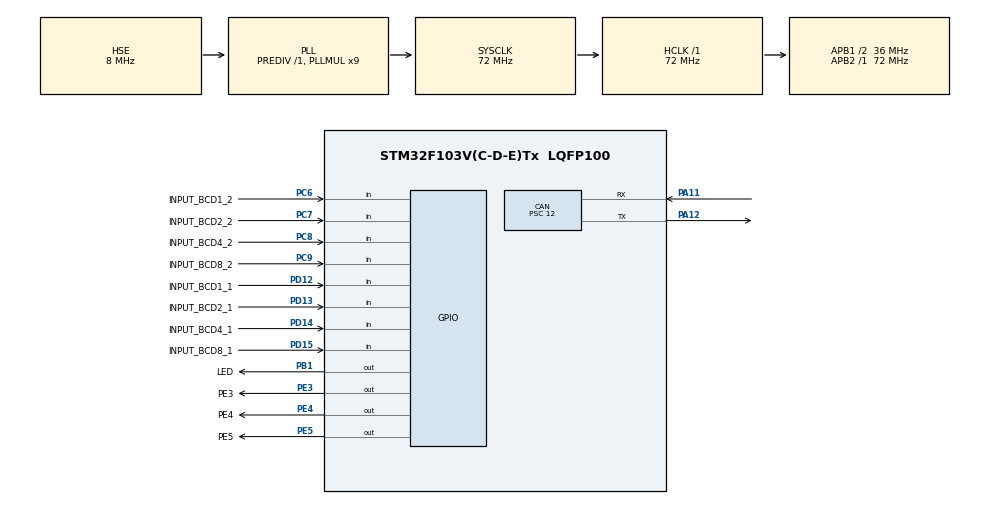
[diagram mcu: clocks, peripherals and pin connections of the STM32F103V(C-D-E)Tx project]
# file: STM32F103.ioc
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CAN.BS1=CAN_BS1_5TQ
CAN.BS2=CAN_BS2_6TQ
CAN.CalculateTimeBit=4000
CAN.CalculateTimeQuantum=333.33333333333337
CAN.Prescaler=12
Mcu.Family=STM32F1
Mcu.Name=STM32F103V(C-D-E)Tx
Mcu.Package=LQFP100
NVIC.PriorityGroup=NVIC_PRIORITYGROUP_4
NVIC.TIM5_IRQn=true\:1\:0\:true\:false\:true\:true
NVIC.USB_LP_CAN1_RX0_IRQn=true\:0\:0\:false\:false\:true\:true
OSC_IN.Mode=HSE-External-Oscillator
OSC_IN.Signal=RCC_OSC_IN
OSC_OUT.Mode=HSE-External-Oscillator
OSC_OUT.Signal=RCC_OSC_OUT
PA11.Mode=Master
PA11.Signal=CAN_RX
PA12.Mode=Master
PA12.Signal=CAN_TX
PA13.Mode=Serial_Wire
PA13.Signal=SYS_JTMS-SWDIO
PA14.Mode=Serial_Wire
PA14.Signal=SYS_JTCK-SWCLK
PB1.GPIO_Label=LED
PB1.Signal=GPIO_Output
PC6.GPIO_Label=INPUT_BCD1_2
PC6.Signal=GPIO_Input
PC7.GPIO_Label=INPUT_BCD2_2
PC7.Signal=GPIO_Input
PC8.GPIO_Label=INPUT_BCD4_2
PC8.Signal=GPIO_Input
PC9.GPIO_Label=INPUT_BCD8_2
PC9.Signal=GPIO_Input
PD12.GPIO_Label=INPUT_BCD1_1
PD12.Signal=GPIO_Input
PD13.GPIO_Label=INPUT_BCD2_1
PD13.Signal=GPIO_Input
PD14.GPIO_Label=INPUT_BCD4_1
PD14.Signal=GPIO_Input
PD15.GPIO_Label=INPUT_BCD8_1
PD15.Signal=GPIO_Input
PE3.GPIO_Label=PE3
PE3.PinState=GPIO_PIN_SET
PE3.Signal=GPIO_Output
PE4.GPIO_Label=PE4
PE4.PinState=GPIO_PIN_SET
PE4.Signal=GPIO_Output
PE5.GPIO_Label=PE5
PE5.PinState=GPIO_PIN_SET
PE5.Signal=GPIO_Output
ProjectManager.HeapSize=0x200
ProjectManager.StackSize=0x400
ProjectManager.TargetToolchain=MDK-ARM V5
RCC.AHBFreq_Value=72000000
RCC.APB1CLKDivider=RCC_HCLK_DIV2
RCC.APB1Freq_Value=36000000
RCC.APB1TimFreq_Value=72000000
RCC.APB2Freq_Value=72000000
RCC.APB2TimFreq_Value=72000000
RCC.HCLKFreq_Value=72000000
RCC.PLLMUL=RCC_PLL_MUL9
RCC.PLLSourceVirtual=RCC_PLLSOURCE_HSE
RCC.SYSCLKFreq_VALUE=72000000
RCC.SYSCLKSource=RCC_SYSCLKSOURCE_PLLCLK
RCC.USBFreq_Value=72000000
TIM5.Period=20000-1
TIM5.Prescaler=7200-1
VP_TIM5_VS_ClockSourceINT.Mode=Internal
board=STM32F103

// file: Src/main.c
/**
  ******************************************************************************
  * File Name          : main.c
  * Description        : Main program body
  ******************************************************************************
  ** This notice applies to any and all portions of this file
  * that are not between comment pairs USER CODE BEGIN and
  * USER CODE END. Other portions of this file, whether
  * inserted by the user or by software development tools
  * are owned by their respective copyright owners.
  *
  * COPYRIGHT(c) 2018 STMicroelectronics
  *
  * Redistribution and use in source and binary forms, with or without modification,
  * are permitted provided that the following conditions are met:
  *   1. Redistributions of source code must retain the above copyright notice,
  *      this list of conditions and the following disclaimer.
  *   2. Redistributions in binary form must reproduce the above copyright notice,
  *      this list of conditions and the following disclaimer in the documentation
  *      and/or other materials provided with the distribution.
  *   3. Neither the name of STMicroelectronics nor the names of its contributors
  *      may be used to endorse or promote products derived from this software
  *      without specific prior written permission.
  *
  * THIS SOFTWARE IS PROVIDED BY THE COPYRIGHT HOLDERS AND CONTRIBUTORS "AS IS"
  * AND ANY EXPRESS OR IMPLIED WARRANTIES, INCLUDING, BUT NOT LIMITED TO, THE
  * IMPLIED WARRANTIES OF MERCHANTABILITY AND FITNESS FOR A PARTICULAR PURPOSE ARE
  * DISCLAIMED. IN NO EVENT SHALL THE COPYRIGHT HOLDER OR CONTRIBUTORS BE LIABLE
  * FOR ANY DIRECT, INDIRECT, INCIDENTAL, SPECIAL, EXEMPLARY, OR CONSEQUENTIAL
  * DAMAGES (INCLUDING, BUT NOT LIMITED TO, PROCUREMENT OF SUBSTITUTE GOODS OR
  * SERVICES; LOSS OF USE, DATA, OR PROFITS; OR BUSINESS INTERRUPTION) HOWEVER
  * CAUSED AND ON ANY THEORY OF LIABILITY, WHETHER IN CONTRACT, STRICT LIABILITY,
  * OR TORT (INCLUDING NEGLIGENCE OR OTHERWISE) ARISING IN ANY WAY OUT OF THE USE
  * OF THIS SOFTWARE, EVEN IF ADVISED OF THE POSSIBILITY OF SUCH DAMAGE.
  *
  ******************************************************************************
  */

#include "main.h"
#include "stm32f1xx_hal.h"

/* USER CODE BEGIN Includes */
#include "user_can.h"
#include "user_io.h"
#include "user_config.h"
#include "user_time.h"
/* USER CODE END Includes */

CAN_HandleTypeDef hcan;

TIM_HandleTypeDef htim5;

/* USER CODE BEGIN PV */
/* Private variables ---------------------------------------------------------*/

/* USER CODE END PV */

void SystemClock_Config(void);
static void MX_GPIO_Init(void);
static void MX_CAN_Init(void);
static void MX_TIM5_Init(void);

/* USER CODE BEGIN PFP */
/* Private function prototypes -----------------------------------------------*/

/* USER CODE END PFP */

int main(void)
{

  /* MCU Configuration----------------------------------------------------------*/

  /* Reset of all peripherals, Initializes the Flash interface and the Systick. */
  HAL_Init();

  /* Configure the system clock */
  SystemClock_Config();

  /* Initialize all configured peripherals */
  MX_GPIO_Init();
  MX_CAN_Init();
  MX_TIM5_Init();

  /* USER CODE BEGIN 2 */
	get_bcd();
	user_can_init();
  /* USER CODE END 2 */

  /* Infinite loop */
  while (1)
  {

  /* USER CODE BEGIN 3 */
		time_event();
  }
  /* USER CODE END 3 */

}

/** System Clock Configuration
*/
void SystemClock_Config(void)
{

  RCC_OscInitTypeDef RCC_OscInitStruct;
  RCC_ClkInitTypeDef RCC_ClkInitStruct;

    /**Initializes the CPU, AHB and APB busses clocks
    */
  RCC_OscInitStruct.OscillatorType = RCC_OSCILLATORTYPE_HSE;
  RCC_OscInitStruct.HSEState = RCC_HSE_ON;
  RCC_OscInitStruct.HSEPredivValue = RCC_HSE_PREDIV_DIV1;
  RCC_OscInitStruct.HSIState = RCC_HSI_ON;
  RCC_OscInitStruct.PLL.PLLState = RCC_PLL_ON;
  RCC_OscInitStruct.PLL.PLLSource = RCC_PLLSOURCE_HSE;
  RCC_OscInitStruct.PLL.PLLMUL = RCC_PLL_MUL9;
  if (HAL_RCC_OscConfig(&RCC_OscInitStruct) != HAL_OK)
  {
    _Error_Handler(__FILE__, __LINE__);
  }

    /**Initializes the CPU, AHB and APB busses clocks
    */
  RCC_ClkInitStruct.ClockType = RCC_CLOCKTYPE_HCLK|RCC_CLOCKTYPE_SYSCLK
                              |RCC_CLOCKTYPE_PCLK1|RCC_CLOCKTYPE_PCLK2;
  RCC_ClkInitStruct.SYSCLKSource = RCC_SYSCLKSOURCE_PLLCLK;
  RCC_ClkInitStruct.AHBCLKDivider = RCC_SYSCLK_DIV1;
  RCC_ClkInitStruct.APB1CLKDivider = RCC_HCLK_DIV2;
  RCC_ClkInitStruct.APB2CLKDivider = RCC_HCLK_DIV1;

  if (HAL_RCC_ClockConfig(&RCC_ClkInitStruct, FLASH_LATENCY_2) != HAL_OK)
  {
    _Error_Handler(__FILE__, __LINE__);
  }

    /**Configure the Systick interrupt time
    */
  HAL_SYSTICK_Config(HAL_RCC_GetHCLKFreq()/1000);

    /**Configure the Systick
    */
  HAL_SYSTICK_CLKSourceConfig(SYSTICK_CLKSOURCE_HCLK);

  /* SysTick_IRQn interrupt configuration */
  HAL_NVIC_SetPriority(SysTick_IRQn, 0, 0);
}

/* CAN init function */
static void MX_CAN_Init(void)
{

  hcan.Instance = CAN1;
  hcan.Init.Prescaler = 12;
  hcan.Init.Mode = CAN_MODE_NORMAL;
  hcan.Init.SJW = CAN_SJW_1TQ;
  hcan.Init.BS1 = CAN_BS1_5TQ;
  hcan.Init.BS2 = CAN_BS2_6TQ;
  hcan.Init.TTCM = DISABLE;
  hcan.Init.ABOM = DISABLE;
  hcan.Init.AWUM = DISABLE;
  hcan.Init.NART = DISABLE;
  hcan.Init.RFLM = DISABLE;
  hcan.Init.TXFP = DISABLE;
  if (HAL_CAN_Init(&hcan) != HAL_OK)
  {
    _Error_Handler(__FILE__, __LINE__);
  }

}

/* TIM5 init function */
static void MX_TIM5_Init(void)
{

  TIM_ClockConfigTypeDef sClockSourceConfig;
  TIM_MasterConfigTypeDef sMasterConfig;

  htim5.Instance = TIM5;
  htim5.Init.Prescaler = 7200-1;
  htim5.Init.CounterMode = TIM_COUNTERMODE_UP;
  htim5.Init.Period = 20000-1;
  htim5.Init.ClockDivision = TIM_CLOCKDIVISION_DIV1;
  htim5.Init.AutoReloadPreload = TIM_AUTORELOAD_PRELOAD_DISABLE;
  if (HAL_TIM_Base_Init(&htim5) != HAL_OK)
  {
    _Error_Handler(__FILE__, __LINE__);
  }

  sClockSourceConfig.ClockSource = TIM_CLOCKSOURCE_INTERNAL;
  if (HAL_TIM_ConfigClockSource(&htim5, &sClockSourceConfig) != HAL_OK)
  {
    _Error_Handler(__FILE__, __LINE__);
  }

  sMasterConfig.MasterOutputTrigger = TIM_TRGO_RESET;
  sMasterConfig.MasterSlaveMode = TIM_MASTERSLAVEMODE_DISABLE;
  if (HAL_TIMEx_MasterConfigSynchronization(&htim5, &sMasterConfig) != HAL_OK)
  {
    _Error_Handler(__FILE__, __LINE__);
  }

}

/** Configure pins as
        * Analog
        * Input
        * Output
        * EVENT_OUT
        * EXTI
*/
static void MX_GPIO_Init(void)
{

  GPIO_InitTypeDef GPIO_InitStruct;

  /* GPIO Ports Clock Enable */
  __HAL_RCC_GPIOE_CLK_ENABLE();
  __HAL_RCC_GPIOB_CLK_ENABLE();
  __HAL_RCC_GPIOD_CLK_ENABLE();
  __HAL_RCC_GPIOC_CLK_ENABLE();
  __HAL_RCC_GPIOA_CLK_ENABLE();

  /*Configure GPIO pin Output Level */
  HAL_GPIO_WritePin(GPIOE, PE3_Pin|PE4_Pin|PE5_Pin, GPIO_PIN_SET);

  /*Configure GPIO pin Output Level */
  HAL_GPIO_WritePin(LED_GPIO_Port, LED_Pin, GPIO_PIN_RESET);

  /*Configure GPIO pins : PE3_Pin PE4_Pin PE5_Pin */
  GPIO_InitStruct.Pin = PE3_Pin|PE4_Pin|PE5_Pin;
  GPIO_InitStruct.Mode = GPIO_MODE_OUTPUT_PP;
  GPIO_InitStruct.Speed = GPIO_SPEED_FREQ_LOW;
  HAL_GPIO_Init(GPIOE, &GPIO_InitStruct);

  /*Configure GPIO pin : LED_Pin */
  GPIO_InitStruct.Pin = LED_Pin;
  GPIO_InitStruct.Mode = GPIO_MODE_OUTPUT_PP;
  GPIO_InitStruct.Speed = GPIO_SPEED_FREQ_LOW;
  HAL_GPIO_Init(LED_GPIO_Port, &GPIO_InitStruct);

  /*Configure GPIO pins : INPUT_BCD1_1_Pin INPUT_BCD2_1_Pin INPUT_BCD4_1_Pin INPUT_BCD8_1_Pin */
  GPIO_InitStruct.Pin = INPUT_BCD1_1_Pin|INPUT_BCD2_1_Pin|INPUT_BCD4_1_Pin|INPUT_BCD8_1_Pin;
  GPIO_InitStruct.Mode = GPIO_MODE_INPUT;
  GPIO_InitStruct.Pull = GPIO_NOPULL;
  HAL_GPIO_Init(GPIOD, &GPIO_InitStruct);

  /*Configure GPIO pins : INPUT_BCD1_2_Pin INPUT_BCD2_2_Pin INPUT_BCD4_2_Pin INPUT_BCD8_2_Pin */
  GPIO_InitStruct.Pin = INPUT_BCD1_2_Pin|INPUT_BCD2_2_Pin|INPUT_BCD4_2_Pin|INPUT_BCD8_2_Pin;
  GPIO_InitStruct.Mode = GPIO_MODE_INPUT;
  GPIO_InitStruct.Pull = GPIO_NOPULL;
  HAL_GPIO_Init(GPIOC, &GPIO_InitStruct);

}

void _Error_Handler(char * file, int line)
{
  while(1)
  {
  }
}

/************************ (C) COPYRIGHT STMicroelectronics *****END OF FILE****/
